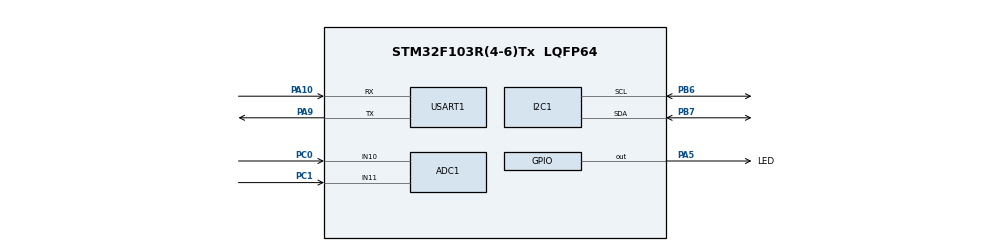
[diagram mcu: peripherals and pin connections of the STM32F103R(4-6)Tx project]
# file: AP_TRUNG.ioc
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ADC1.Channel-0\#ChannelRegularConversion=ADC_CHANNEL_10
ADC1.Channel-1\#ChannelRegularConversion=ADC_CHANNEL_11
ADC1.ContinuousConvMode=DISABLE
ADC1.DiscontinuousConvMode=DISABLE
ADC1.NbrOfConversion=2
ADC1.NbrOfConversionFlag=1
ADC1.Rank-0\#ChannelRegularConversion=1
ADC1.Rank-1\#ChannelRegularConversion=2
ADC1.SamplingTime-0\#ChannelRegularConversion=ADC_SAMPLETIME_239CYCLES_5
ADC1.SamplingTime-1\#ChannelRegularConversion=ADC_SAMPLETIME_71CYCLES_5
ADC1.master=1
Dma.ADC1.0.Direction=DMA_PERIPH_TO_MEMORY
Dma.ADC1.0.Instance=DMA1_Channel1
Dma.ADC1.0.MemDataAlignment=DMA_MDATAALIGN_HALFWORD
Dma.ADC1.0.MemInc=DMA_MINC_ENABLE
Dma.ADC1.0.Mode=DMA_NORMAL
Dma.ADC1.0.PeriphDataAlignment=DMA_PDATAALIGN_HALFWORD
Dma.ADC1.0.PeriphInc=DMA_PINC_DISABLE
Dma.ADC1.0.Priority=DMA_PRIORITY_LOW
Dma.Request0=ADC1
Mcu.Family=STM32F1
Mcu.Name=STM32F103R(4-6)Tx
Mcu.Package=LQFP64
NVIC.DMA1_Channel1_IRQn=true\:0\:0\:false\:false\:true\:false\:true\:true
NVIC.PriorityGroup=NVIC_PRIORITYGROUP_4
PA10.Mode=Asynchronous
PA10.Signal=USART1_RX
PA13.Mode=Serial_Wire
PA13.Signal=SYS_JTMS-SWDIO
PA14.Mode=Serial_Wire
PA14.Signal=SYS_JTCK-SWCLK
PA5.GPIO_Label=LED
PA5.Signal=GPIO_Output
PA9.Mode=Asynchronous
PA9.Signal=USART1_TX
PB6.Mode=I2C
PB6.Signal=I2C1_SCL
PB7.Mode=I2C
PB7.Signal=I2C1_SDA
PC0.Signal=ADCx_IN10
PC1.Signal=ADCx_IN11
ProjectManager.HeapSize=0x200
ProjectManager.StackSize=0x400
ProjectManager.TargetToolchain=MDK-ARM V5.32
RCC.APB1Freq_Value=8000000
RCC.APB2Freq_Value=8000000
SH.ADCx_IN10.0=ADC1_IN10,IN10
SH.ADCx_IN11.0=ADC1_IN11,IN11
USART1.VirtualMode=VM_ASYNC
board=custom

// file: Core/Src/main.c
/* USER CODE BEGIN Header */
/**
  ******************************************************************************
  * @file           : main.c
  * @brief          : Main program body
  ******************************************************************************
  * @attention
  *
  * Copyright (c) 2024 STMicroelectronics.
  * All rights reserved.
  *
  * This software is licensed under terms that can be found in the LICENSE file
  * in the root directory of this software component.
  * If no LICENSE file comes with this software, it is provided AS-IS.
  *
  ******************************************************************************
  */
/* USER CODE END Header */
#include "main.h"
#include "adc.h"
#include "dma.h"
#include "i2c.h"
#include "usart.h"
#include "gpio.h"

/* USER CODE BEGIN Includes */
#include "stdio.h"
#include "string.h"
/* USER CODE END Includes */

void SystemClock_Config(void);

/* USER CODE BEGIN 0 */
uint16_t valueAdcLm35[2];
uint8_t data[10];
/* USER CODE END 0 */

int main(void)
{

  /* MCU Configuration--------------------------------------------------------*/

  /* Reset of all peripherals, Initializes the Flash interface and the Systick. */
  HAL_Init();

  /* Configure the system clock */
  SystemClock_Config();

  /* Initialize all configured peripherals */
  MX_GPIO_Init();
  MX_DMA_Init();
  MX_ADC1_Init();
  MX_I2C1_Init();
  MX_USART1_UART_Init();
  /* USER CODE BEGIN 2 */
	HAL_ADC_Start_DMA(&hadc1,(uint32_t*)valueAdcLm35,2);
  /* USER CODE END 2 */

  /* Infinite loop */
  /* USER CODE BEGIN WHILE */
  while (1)
  {
		HAL_ADC_Start_DMA(&hadc1,(uint32_t*)valueAdcLm35,2);
		sprintf((char*)data, "%d %d\n", valueAdcLm35[0], valueAdcLm35[1]);
		HAL_UART_Transmit(&huart1, data, sizeof(data), 1000);
		//HAL_UART_Transmit(&huart1, (uint8_t*)"x", 1, 1000);
		HAL_GPIO_TogglePin(LED_GPIO_Port, LED_Pin);
		HAL_Delay(1000);
    /* USER CODE END WHILE */

  }
}

void SystemClock_Config(void)
{
  RCC_OscInitTypeDef RCC_OscInitStruct = {0};
  RCC_ClkInitTypeDef RCC_ClkInitStruct = {0};
  RCC_PeriphCLKInitTypeDef PeriphClkInit = {0};

  /** Initializes the RCC Oscillators according to the specified parameters
  * in the RCC_OscInitTypeDef structure.
  */
  RCC_OscInitStruct.OscillatorType = RCC_OSCILLATORTYPE_HSI;
  RCC_OscInitStruct.HSIState = RCC_HSI_ON;
  RCC_OscInitStruct.HSICalibrationValue = RCC_HSICALIBRATION_DEFAULT;
  RCC_OscInitStruct.PLL.PLLState = RCC_PLL_NONE;
  if (HAL_RCC_OscConfig(&RCC_OscInitStruct) != HAL_OK)
  {
    Error_Handler();
  }

  /** Initializes the CPU, AHB and APB buses clocks
  */
  RCC_ClkInitStruct.ClockType = RCC_CLOCKTYPE_HCLK|RCC_CLOCKTYPE_SYSCLK
                              |RCC_CLOCKTYPE_PCLK1|RCC_CLOCKTYPE_PCLK2;
  RCC_ClkInitStruct.SYSCLKSource = RCC_SYSCLKSOURCE_HSI;
  RCC_ClkInitStruct.AHBCLKDivider = RCC_SYSCLK_DIV1;
  RCC_ClkInitStruct.APB1CLKDivider = RCC_HCLK_DIV1;
  RCC_ClkInitStruct.APB2CLKDivider = RCC_HCLK_DIV1;

  if (HAL_RCC_ClockConfig(&RCC_ClkInitStruct, FLASH_LATENCY_0) != HAL_OK)
  {
    Error_Handler();
  }
  PeriphClkInit.PeriphClockSelection = RCC_PERIPHCLK_ADC;
  PeriphClkInit.AdcClockSelection = RCC_ADCPCLK2_DIV2;
  if (HAL_RCCEx_PeriphCLKConfig(&PeriphClkInit) != HAL_OK)
  {
    Error_Handler();
  }
}

void Error_Handler(void)
{
  __disable_irq();
  while (1)
  {
  }
}
